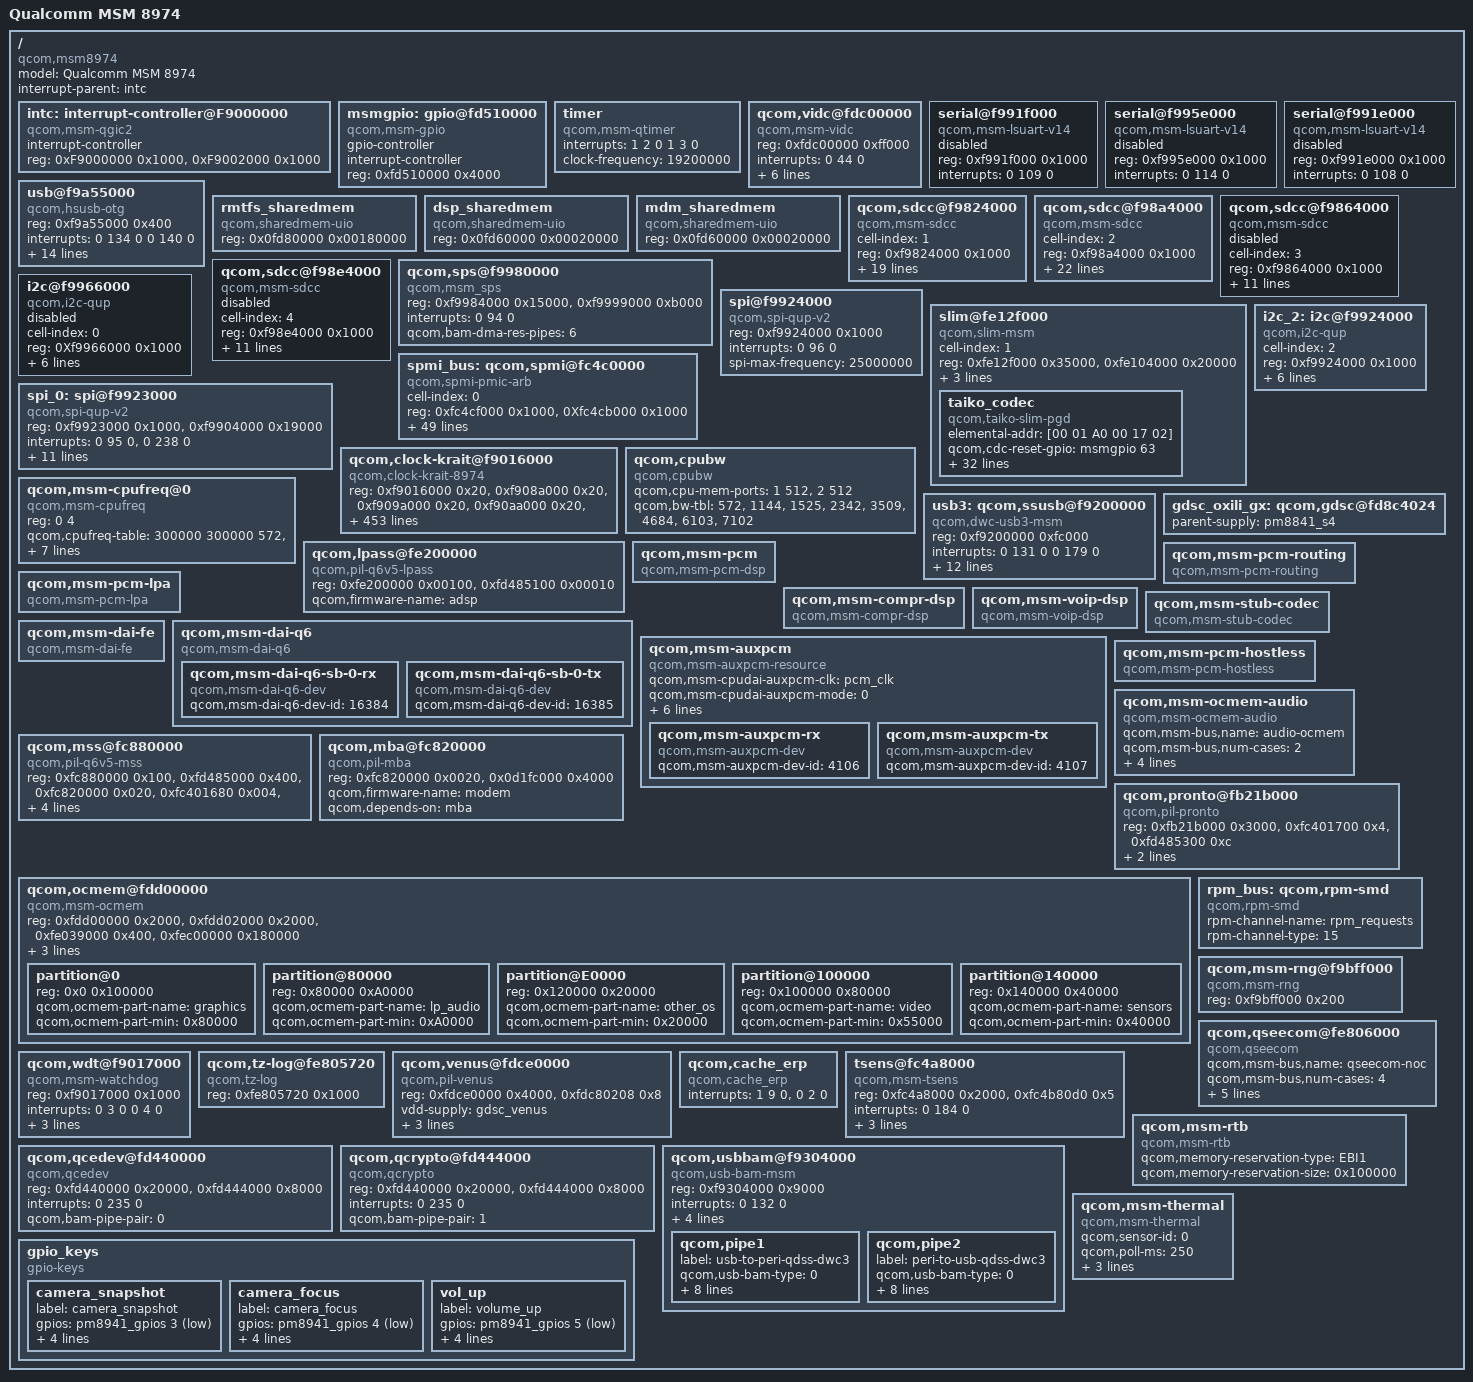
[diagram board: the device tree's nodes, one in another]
/* Copyright (c) 2012, The Linux Foundation. All rights reserved.
 *
 * This program is free software; you can redistribute it and/or modify
 * it under the terms of the GNU General Public License version 2 and
 * only version 2 as published by the Free Software Foundation.
 *
 * This program is distributed in the hope that it will be useful,
 * but WITHOUT ANY WARRANTY; without even the implied warranty of
 * MERCHANTABILITY or FITNESS FOR A PARTICULAR PURPOSE.  See the
 * GNU General Public License for more details.
 */

/include/ "skeleton.dtsi"
/include/ "msm8974_pm.dtsi"
/include/ "msm8974-iommu.dtsi"
/include/ "msm8974-camera.dtsi"
/include/ "msm8974-coresight.dtsi"
/include/ "msm-gdsc.dtsi"
/include/ "msm8974-ion.dtsi"
/include/ "msm8974-gpu.dtsi"
/include/ "msm8974-mdss.dtsi"

/ {
	model = "Qualcomm MSM 8974";
	compatible = "qcom,msm8974";
	interrupt-parent = <&intc>;

	intc: interrupt-controller@F9000000 {
		compatible = "qcom,msm-qgic2";
		interrupt-controller;
		#interrupt-cells = <3>;
		reg = <0xF9000000 0x1000>,
		      <0xF9002000 0x1000>;
	};

	msmgpio: gpio@fd510000 {
		compatible = "qcom,msm-gpio";
		gpio-controller;
		#gpio-cells = <2>;
		interrupt-controller;
		#interrupt-cells = <2>;
		reg = <0xfd510000 0x4000>;
	};

	timer {
		compatible = "qcom,msm-qtimer", "arm,armv7-timer";
		interrupts = <1 2 0 1 3 0>;
		clock-frequency = <19200000>;
	};

	qcom,vidc@fdc00000 {
		compatible = "qcom,msm-vidc";
		reg = <0xfdc00000 0xff000>;
		interrupts = <0 44 0>;
		vidc-cp-map = <0x1000000 0x40000000>;
		vidc-ns-map = <0x40000000 0x40000000>;
		load-freq-tbl = <979200 410000000>,
				<560145 266670000>,
				<421161 200000000>,
				<243000 133330000>,
				<108000 100000000>,
				<36000 50000000>;
	};

	serial@f991f000 {
		compatible = "qcom,msm-lsuart-v14";
		reg = <0xf991f000 0x1000>;
		interrupts = <0 109 0>;
		status = "disabled";
	};

	serial@f995e000 {
		compatible = "qcom,msm-lsuart-v14";
		reg = <0xf995e000 0x1000>;
		interrupts = <0 114 0>;
		status = "disabled";
	};

	serial@f991e000 {
		compatible = "qcom,msm-lsuart-v14";
		reg = <0xf991e000 0x1000>;
		interrupts = <0 108 0>;
		status = "disabled";
	};

	usb@f9a55000 {
		compatible = "qcom,hsusb-otg";
		reg = <0xf9a55000 0x400>;
		interrupts = <0 134 0 0 140 0>;
		interrupt-names = "core_irq", "async_irq";
		HSUSB_VDDCX-supply = <&pm8841_s2>;
		HSUSB_1p8-supply = <&pm8941_l6>;
		HSUSB_3p3-supply = <&pm8941_l24>;

		qcom,hsusb-otg-phy-type = <2>;
		qcom,hsusb-otg-mode = <1>;
		qcom,hsusb-otg-otg-control = <1>;
		qcom,hsusb-otg-disable-reset;
		qcom,hsusb-otg-pnoc-errata-fix;

		qcom,msm-bus,name = "usb2";
		qcom,msm-bus,num-cases = <2>;
		qcom,msm-bus,active-only = <0>;
		qcom,msm-bus,num-paths = <1>;
		qcom,msm-bus,vectors-KBps =
				<87 512 0 0>,
				<87 512 60000 960000>;
	};

	rmtfs_sharedmem {
		compatible = "qcom,sharedmem-uio";
		reg = <0x0fd80000 0x00180000>;
		reg-names = "rmtfs";
	};

	dsp_sharedmem {
		compatible = "qcom,sharedmem-uio";
		reg = <0x0fd60000 0x00020000>;
		reg-names = "rfsa_dsp";
	};

	mdm_sharedmem {
		compatible = "qcom,sharedmem-uio";
		reg = <0x0fd60000 0x00020000>;
		reg-names = "rfsa_mdm";
	};

	qcom,sdcc@f9824000 {
		cell-index = <1>; /* SDC1 eMMC slot */
		compatible = "qcom,msm-sdcc";
		reg = <0xf9824000 0x1000>;
		reg-names = "core_mem";
		interrupts = <0 123 0>;
		interrupt-names = "core_irq";
		vdd-supply = <&pm8941_l20>;
		vdd-io-supply = <&pm8941_s3>;

		qcom,sdcc-vdd-voltage_level = <2950000 2950000>;
		qcom,sdcc-vdd-current_level = <800 500000>;

		qcom,sdcc-vdd-io-always_on;
		qcom,sdcc-vdd-io-voltage_level = <1800000 1800000>;
		qcom,sdcc-vdd-io-current_level = <250 154000>;

		qcom,sdcc-pad-pull-on = <0x0 0x3 0x3>; /* no-pull, pull-up, pull-up */
		qcom,sdcc-pad-pull-off = <0x0 0x3 0x3>; /* no-pull, pull-up, pull-up */
		qcom,sdcc-pad-drv-on = <0x7 0x4 0x4>; /* 16mA, 10mA, 10mA */
		qcom,sdcc-pad-drv-off = <0x0 0x0 0x0>; /* 2mA, 2mA, 2mA */

		qcom,sdcc-clk-rates = <400000 25000000 50000000 100000000 200000000>;
		qcom,sdcc-sup-voltages = <2950 2950>;
		qcom,sdcc-bus-width = <8>;
		qcom,sdcc-nonremovable;
		qcom,sdcc-bus-speed-mode = "HS200_1p8v", "DDR_1p8v";
	};

	qcom,sdcc@f98a4000 {
		cell-index = <2>; /* SDC2 SD card slot */
		compatible = "qcom,msm-sdcc";
		reg = <0xf98a4000 0x1000>;
		reg-names = "core_mem";
		interrupts = <0 125 0>;
		interrupt-names = "core_irq";
		vdd-supply = <&pm8941_l21>;
		vdd-io-supply = <&pm8941_l13>;

		qcom,sdcc-vdd-voltage_level = <2950000 2950000>;
		qcom,sdcc-vdd-current_level = <9000 800000>;

		qcom,sdcc-vdd-io-always_on;
		qcom,sdcc-vdd-io-lpm_sup;
		qcom,sdcc-vdd-io-voltage_level = <1800000 2950000>;
		qcom,sdcc-vdd-io-current_level = <6 22000>;

		qcom,sdcc-pad-pull-on = <0x0 0x3 0x3>; /* no-pull, pull-up, pull-up */
		qcom,sdcc-pad-pull-off = <0x0 0x3 0x3>; /* no-pull, pull-up, pull-up */
		qcom,sdcc-pad-drv-on = <0x7 0x4 0x4>; /* 16mA, 10mA, 10mA */
		qcom,sdcc-pad-drv-off = <0x0 0x0 0x0>; /* 2mA, 2mA, 2mA */

		qcom,sdcc-clk-rates = <400000 25000000 50000000 100000000 200000000>;
		qcom,sdcc-sup-voltages = <2950 2950>;
		qcom,sdcc-bus-width = <4>;
		qcom,sdcc-xpc;
		qcom,sdcc-bus-speed-mode = "SDR12", "SDR25", "SDR50", "DDR50", "SDR104";
		qcom,sdcc-current-limit = <800>;
	};

	qcom,sdcc@f9864000 {
		cell-index = <3>; /* SDC3 SDIO slot */
		compatible = "qcom,msm-sdcc";
		reg = <0xf9864000 0x1000>;
		reg-names = "core_mem";
		interrupts = <0 127 0>;
		interrupt-names = "core_irq";

		gpios = <&msmgpio 40 0>, /* CLK */
			<&msmgpio 39 0>, /* CMD */
			<&msmgpio 38 0>, /* DATA0 */
			<&msmgpio 37 0>, /* DATA1 */
			<&msmgpio 36 0>, /* DATA2 */
			<&msmgpio 35 0>; /* DATA3 */
		qcom,sdcc-gpio-names = "CLK", "CMD", "DAT0", "DAT1", "DAT2", "DAT3";

		qcom,sdcc-clk-rates = <400000 25000000 50000000 100000000>;
		qcom,sdcc-sup-voltages = <1800 1800>;
		qcom,sdcc-bus-width = <4>;
		qcom,sdcc-bus-speed-mode = "SDR12", "SDR25", "SDR50", "DDR50";
		status = "disable";
	};

	qcom,sdcc@f98e4000 {
		cell-index = <4>; /* SDC4 SDIO slot */
		compatible = "qcom,msm-sdcc";
		reg = <0xf98e4000 0x1000>;
		reg-names = "core_mem";
		interrupts = <0 129 0>;
		interrupt-names = "core_irq";

		gpios = <&msmgpio 93 0>, /* CLK */
			<&msmgpio 91 0>, /* CMD */
			<&msmgpio 96 0>, /* DATA0 */
			<&msmgpio 95 0>, /* DATA1 */
			<&msmgpio 94 0>, /* DATA2 */
			<&msmgpio 92 0>; /* DATA3 */
		qcom,sdcc-gpio-names = "CLK", "CMD", "DAT0", "DAT1", "DAT2", "DAT3";

		qcom,sdcc-clk-rates = <400000 25000000 50000000 100000000>;
		qcom,sdcc-sup-voltages = <1800 1800>;
		qcom,sdcc-bus-width = <4>;
		qcom,sdcc-bus-speed-mode = "SDR12", "SDR25", "SDR50", "DDR50";
		status = "disable";
	};

	qcom,sps@f9980000 {
		compatible = "qcom,msm_sps";
		reg = <0xf9984000 0x15000>,
		      <0xf9999000 0xb000>;
		interrupts = <0 94 0>;

		qcom,bam-dma-res-pipes = <6>;
	};


	spi@f9924000 {
		compatible = "qcom,spi-qup-v2";
		reg = <0xf9924000 0x1000>;
		interrupts = <0 96 0>;
		spi-max-frequency = <25000000>;
	};

	slim@fe12f000 {
		cell-index = <1>;
		compatible = "qcom,slim-msm";
		reg = <0xfe12f000 0x35000>,
		      <0xfe104000 0x20000>;
		reg-names = "slimbus_physical", "slimbus_bam_physical";
		interrupts = <0 163 0 0 164 0>;
		interrupt-names = "slimbus_irq", "slimbus_bam_irq";
		qcom,min-clk-gear = <10>;
		qcom,rxreg-access;

		taiko_codec {
			compatible = "qcom,taiko-slim-pgd";
			elemental-addr = [00 01 A0 00 17 02];

			qcom,cdc-reset-gpio = <&msmgpio 63 0>;

			cdc-vdd-buck-supply = <&pm8941_s2>;
			qcom,cdc-vdd-buck-voltage = <2150000 2150000>;
			qcom,cdc-vdd-buck-current = <650000>;

			cdc-vdd-tx-h-supply = <&pm8941_s3>;
			qcom,cdc-vdd-tx-h-voltage = <1800000 1800000>;
			qcom,cdc-vdd-tx-h-current = <25000>;

			cdc-vdd-rx-h-supply = <&pm8941_s3>;
			qcom,cdc-vdd-rx-h-voltage = <1800000 1800000>;
			qcom,cdc-vdd-rx-h-current = <25000>;

			cdc-vddpx-1-supply = <&pm8941_s3>;
			qcom,cdc-vddpx-1-voltage = <1800000 1800000>;
			qcom,cdc-vddpx-1-current = <10000>;

			cdc-vdd-a-1p2v-supply = <&pm8941_l1>;
			qcom,cdc-vdd-a-1p2v-voltage = <1225000 1225000>;
			qcom,cdc-vdd-a-1p2v-current = <10000>;

			cdc-vddcx-1-supply = <&pm8941_l1>;
			qcom,cdc-vddcx-1-voltage = <1225000 1225000>;
			qcom,cdc-vddcx-1-current = <10000>;

			cdc-vddcx-2-supply = <&pm8941_l1>;
			qcom,cdc-vddcx-2-voltage = <1225000 1225000>;
			qcom,cdc-vddcx-2-current = <10000>;

			qcom,cdc-micbias-ldoh-v = <0x3>;
			qcom,cdc-micbias-cfilt1-mv = <1800>;
			qcom,cdc-micbias-cfilt2-mv = <2700>;
			qcom,cdc-micbias-cfilt3-mv = <1800>;
			qcom,cdc-micbias1-cfilt-sel = <0x0>;
			qcom,cdc-micbias2-cfilt-sel = <0x1>;
			qcom,cdc-micbias3-cfilt-sel = <0x2>;
			qcom,cdc-micbias4-cfilt-sel = <0x2>;

			qcom,cdc-slim-ifd = "taiko-slim-ifd";
			qcom,cdc-slim-ifd-elemental-addr = [00 00 A0 00 17 02];
		};
	};

	spmi_bus: qcom,spmi@fc4c0000 {
		cell-index = <0>;
		compatible = "qcom,spmi-pmic-arb";
		reg = <0xfc4cf000 0x1000>,
		      <0Xfc4cb000 0x1000>;
		/* 190,ee0_krait_hlos_spmi_periph_irq */
		/* 187,channel_0_krait_hlos_trans_done_irq */
		interrupts = <0 190 0 0 187 0>;
		qcom,pmic-arb-ee = <0>;
		qcom,pmic-arb-channel = <0>;
		qcom,pmic-arb-ppid-map = <0x40400000>, /* BUS */
					 <0x40500001>, /* INT */
					 <0x40600002>, /* SPMI */
					 <0x40800003>, /* PON */
					 <0x42400004>, /* TEMP_ALARM */
					 <0x47000005>, /* PBS_CORE */
					 <0x47100006>, /* PBS_CLIENT0 */
					 <0x47200007>, /* PBS_CLIENT1 */
					 <0x47300008>, /* PBS_CLIENT2 */
					 <0x47400009>, /* PBS_CLIENT3 */
					 <0x4750000a>, /* PBS_CLIENT4 */
					 <0x4760000b>, /* PBS_CLIENT5 */
					 <0x4770000c>, /* PBS_CLIENT6 */
					 <0x4780000d>, /* PBS_CLIENT7 */
					 <0x4a00000e>, /* MPP1 */
					 <0x4a100021>, /* MPP2 */
					 <0x4a20000f>, /* MPP3 */
					 <0x4a300010>, /* MPP4 */
					 <0x51000011>, /* BCLK_GEN_MAIN */
					 <0x51d00012>, /* S4_CTRL */
					 <0x51e00013>, /* S4_PS */
					 <0x51f00014>, /* S4_FREQ */
					 <0x52000015>, /* S5_CTRL */
					 <0x52100016>, /* S5_PS */
					 <0x52200017>, /* S5_FREQ */
					 <0x52300018>, /* S6_CTRL */
					 <0x52400019>, /* S6_PS */
					 <0x5250001a>, /* S6_FREQ */
					 <0x5260001b>, /* S7_CTRL */
					 <0x5270001c>, /* S7_PS */
					 <0x5280001d>, /* S7_FREQ */
					 <0x5290001e>, /* S8_CTRL */
					 <0x52a0001f>, /* S8_PS */
					 <0x52b00020>, /* S8_FREQ */
					 <0x00400022>, /* BUS */
					 <0x00500023>, /* INT */
					 <0x00600024>, /* SPMI */
					 <0x00800025>, /* PON */
					 <0x00b00027>, /* VREG_TFT */
					 <0x01000028>, /* SMBB_CHGR */
					 <0x01100029>, /* SMBB_BUCK */
					 <0x0120002a>, /* SMBB_BAT_IF */
					 <0x0130002b>, /* SMBB_USB_CHGPTH */
					 <0x0140002c>, /* SMBB_DC_CHGPTH */
					 <0x0150002d>, /* SMBB_BOOST */
					 <0x0160002e>, /* SMBB_MISC */
					 <0x0170002f>, /* SMBB_FREQ */
					 <0x02400030>, /* TEMP_ALARM */
					 <0x02800031>, /* COIN */
					 <0x03100032>, /* VADC1_USR */
					 <0x03300033>, /* VADC1_BMS */
					 <0x03400034>, /* VADC2_BTM */
					 <0x03600035>, /* IADC1_USR */
					 <0x03800036>, /* IADC1_BMS */
					 <0x04000037>, /* BMS1 */
					 <0x05700039>, /* DIFF_CLK1 */
					 <0x05c0003b>, /* DIV_CLK2 */
					 <0x0610003d>, /* RTC_ALARM */
					 <0x0620003e>, /* RTC_TIMER */
					 <0x07100040>, /* PBS_CLIENT0 */
					 <0x07200041>, /* PBS_CLIENT1 */
					 <0x07300042>, /* PBS_CLIENT2 */
					 <0x07400043>, /* PBS_CLIENT3 */
					 <0x07500044>, /* PBS_CLIENT4 */
					 <0x07600045>, /* PBS_CLIENT5 */
					 <0x07700046>, /* PBS_CLIENT6 */
					 <0x07800047>, /* PBS_CLIENT7 */
					 <0x07900048>, /* PBS_CLIENT8 */
					 <0x07a00049>, /* PBS_CLIENT9 */
					 <0x07b0004a>, /* PBS_CLIENT10 */
					 <0x07c0004b>, /* PBS_CLIENT11 */
					 <0x07d0004c>, /* PBS_CLIENT12 */
					 <0x07e0004d>, /* PBS_CLIENT13 */
					 <0x07f0004e>, /* PBS_CLIENT14 */
					 <0x0800004f>, /* PBS_CLIENT15 */
					 <0x0a100050>, /* MPP2 */
					 <0x0a300051>, /* MPP4 */
					 <0x0a400052>, /* MPP5 */
					 <0x0a500053>, /* MPP6 */
					 <0x0a600054>, /* MPP7 */
					 <0x0a700055>, /* MPP8 */
					 <0x0c000056>, /* GPIO1 */
					 <0x0c100057>, /* GPIO2 */
					 <0x0c200058>, /* GPIO3 */
					 <0x0c300059>, /* GPIO4 */
					 <0x0c40005a>, /* GPIO5 */
					 <0x0c50005b>, /* GPIO6 */
					 <0x0c60005c>, /* GPIO7 */
					 <0x0c70005d>, /* GPIO8 */
					 <0x0c80005e>, /* GPIO9 */
					 <0x0c90005f>, /* GPIO10 */
					 <0x0ca00060>, /* GPIO11 */
					 <0x0cb00061>, /* GPIO12 */
					 <0x0cc00062>, /* GPIO13 */
					 <0x0cd00063>, /* GPIO14 */
					 <0x0ce00064>, /* GPIO15 */
					 <0x0cf00065>, /* GPIO16 */
					 <0x0d200066>, /* GPIO19 */
					 <0x0d300067>, /* GPIO20 */
					 <0x0d500068>, /* GPIO22 */
					 <0x0d600069>, /* GPIO23 */
					 <0x0d70006a>, /* GPIO24 */
					 <0x0d80006b>, /* GPIO25 */
					 <0x0d90006c>, /* GPIO26 */
					 <0x0da0006d>, /* GPIO27 */
					 <0x0dc0006e>, /* GPIO29 */
					 <0x0dd0006f>, /* GPIO30 */
					 <0x0df00070>, /* GPIO32 */
					 <0x0e000071>, /* GPIO33 */
					 <0x0e100072>, /* GPIO34 */
					 <0x0e200073>, /* GPIO35 */
					 <0x0e300074>, /* GPIO36 */
					 <0x11000075>, /* BUCK_CMN */
					 <0x1a000076>, /* BOOST */
					 <0x1a100077>, /* BOOST_FREQ */
					 <0x1a800078>, /* KEYPAD1 */
					 <0x1b000079>, /* LPG_LUT */
					 <0x1b10007a>, /* LPG_CHAN1 */
					 <0x1b20007b>, /* LPG_CHAN2 */
					 <0x1b30007c>, /* LPG_CHAN3 */
					 <0x1b40007d>, /* LPG_CHAN4 */
					 <0x1b50007e>, /* LPG_CHAN5 */
					 <0x1b60007f>, /* LPG_CHAN6 */
					 <0x1b700080>, /* LPG_CHAN7 */
					 <0x1b800081>, /* LPG_CHAN8 */
					 <0x1bc00082>, /* PWM_3D */
					 <0x1c000083>, /* VIB1 */
					 <0x1d000084>, /* TRI_LED */
					 <0x1d300085>, /* FLASH1 */
					 <0x1d800086>, /* WLED1 */
					 <0x1e200087>, /* KPDBL_MAIN */
					 <0x1e300088>, /* KPDBL_LUT */
					 <0x1e400089>, /* LPG_CHAN9 */
					 <0x1e50008a>, /* LPG_CHAN10 */
					 <0x1e60008b>, /* LPG_CHAN11 */
					 <0x1e70008c>; /* LPG_CHAN12 */
	};

	i2c@f9966000 {
		cell-index = <0>;
		compatible = "qcom,i2c-qup";
		reg = <0Xf9966000 0x1000>;
		reg-names = "qup_phys_addr";
		interrupts = <0 104 0>;
		interrupt-names = "qup_err_intr";
		qcom,i2c-bus-freq = <100000>;
		qcom,i2c-src-freq = <19200000>;
		qcom,scl-gpio = <&msmgpio 3 0>;
		qcom,sda-gpio = <&msmgpio 2 0>;
		qcom,master-id = <86>;
		status = "disabled";
	};

	i2c_2: i2c@f9924000 {
		cell-index = <2>;
		compatible = "qcom,i2c-qup";
		reg = <0xf9924000 0x1000>;
		#address-cells = <1>;
		#size-cells = <0>;
		reg-names = "qup_phys_addr";
		interrupts = <0 96 0>;
		interrupt-names = "qup_err_intr";
		qcom,i2c-bus-freq = <384000>;
		qcom,i2c-src-freq = <19200000>;
		qcom,master-id = <86>;
		qcom,scl-gpio = <&msmgpio 7 0>;
		qcom,sda-gpio = <&msmgpio 6 0>;
	};

	spi_0: spi@f9923000 { /* BLSP1 QUP1 */
		compatible = "qcom,spi-qup-v2";
		#address-cells = <1>;
		#size-cells = <0>;
		reg-names = "spi_physical", "spi_bam_physical";
		reg = <0xf9923000 0x1000>,
		      <0xf9904000 0x19000>;
		interrupt-names = "spi_irq", "spi_bam_irq";
		interrupts = <0 95 0>, <0 238 0>;
		spi-max-frequency = <19200000>;

		qcom,gpio-mosi = <&msmgpio 0 0>;
		qcom,gpio-miso = <&msmgpio 1 0>;
		qcom,gpio-clk  = <&msmgpio 3 0>;
		qcom,gpio-cs0  = <&msmgpio 9 0>;

		qcom,infinite-mode = <0>;
		qcom,use-bam;
		qcom,ver-reg-exists;
		qcom,bam-consumer-pipe-index = <12>;
		qcom,bam-producer-pipe-index = <13>;
		qcom,master-id = <86>;
	};

	qcom,clock-krait@f9016000 {
		compatible = "qcom,clock-krait-8974";
		reg = <0xf9016000 0x20>,
			<0xf908a000 0x20>,
			<0xf909a000 0x20>,
			<0xf90aa000 0x20>,
			<0xf90ba000 0x20>,
			<0xfc4b80b0 0x08>;
		reg-names = "hfpll_l2_clk", "hfpll0_clk",
				"hfpll1_clk", "hfpll2_clk",
				"hfpll3_clk", "efuse";
		cpu0-supply = <&krait0_vreg>;
		cpu1-supply = <&krait1_vreg>;
		cpu2-supply = <&krait2_vreg>;
		cpu3-supply = <&krait3_vreg>;
		l2-dig-supply = <&pm8841_s2_corner_ao>;
		hfpll-dig-supply = <&pm8841_s2_corner_ao>;
		hfpll-analog-supply = <&pm8941_l12_ao>;
		qcom,hfpll-config-val = <0x04D0405D>;
                qcom,hfpll-user-vco-mask = <0x00100000>;

		qcom,l2-fmax =
			<          0 0			 >,
			<  576000000 4 /* SVS_SOC */	 >,
			< 1036800000 5 /* NORMAL */	 >,
			< 1728000000 7 /* SUPER_TURBO */ >;

		qcom,speed0-pvs0-bin-v0 =
			<          0       0   0 >,
			<  300000000  815000  73 >,
			<  345600000  825000  85 >,
			<  422400000  835000 104 >,
			<  499200000  845000 124 >,
			<  576000000  855000 144 >,
			<  652800000  865000 165 >,
			<  729600000  875000 186 >,
			<  806400000  890000 208 >,
			<  883200000  900000 229 >,
			<  960000000  915000 252 >,
			< 1036800000  925000 275 >,
			< 1113600000  940000 298 >,
			< 1190400000  950000 321 >,
			< 1267200000  965000 346 >,
			< 1344000000  980000 371 >,
			< 1420800000  995000 397 >,
			< 1497600000 1010000 423 >,
			< 1574400000 1025000 450 >,
			< 1651200000 1040000 477 >,
			< 1728000000 1055000 506 >,
			< 1804800000 1070000 536 >,
			< 1881600000 1085000 567 >,
			< 1958400000 1100000 598 >;

		qcom,speed0-pvs1-bin-v0 =
			<          0       0   0 >,
			<  300000000  800000  73 >,
			<  345600000  810000  85 >,
			<  422400000  820000 104 >,
			<  499200000  830000 124 >,
			<  576000000  840000 144 >,
			<  652800000  850000 165 >,
			<  729600000  860000 186 >,
			<  806400000  875000 208 >,
			<  883200000  885000 229 >,
			<  960000000  895000 252 >,
			< 1036800000  910000 275 >,
			< 1113600000  920000 298 >,
			< 1190400000  930000 321 >,
			< 1267200000  945000 346 >,
			< 1344000000  960000 371 >,
			< 1420800000  975000 397 >,
			< 1497600000  990000 423 >,
			< 1574400000 1005000 450 >,
			< 1651200000 1020000 477 >,
			< 1728000000 1030000 506 >,
			< 1804800000 1045000 536 >,
			< 1881600000 1060000 567 >,
			< 1958400000 1075000 598 >;

		qcom,speed0-pvs2-bin-v0 =
			<          0       0   0 >,
			<  300000000  785000  73 >,
			<  345600000  795000  85 >,
			<  422400000  805000 104 >,
			<  499200000  815000 124 >,
			<  576000000  825000 144 >,
			<  652800000  835000 165 >,
			<  729600000  845000 186 >,
			<  806400000  855000 208 >,
			<  883200000  865000 229 >,
			<  960000000  875000 252 >,
			< 1036800000  890000 275 >,
			< 1113600000  900000 298 >,
			< 1190400000  910000 321 >,
			< 1267200000  925000 346 >,
			< 1344000000  940000 371 >,
			< 1420800000  955000 397 >,
			< 1497600000  970000 423 >,
			< 1574400000  980000 450 >,
			< 1651200000  995000 477 >,
			< 1728000000 1005000 506 >,
			< 1804800000 1020000 536 >,
			< 1881600000 1035000 567 >,
			< 1958400000 1050000 598 >;

		qcom,speed0-pvs3-bin-v0 =
			<          0       0   0 >,
			<  300000000  775000  73 >,
			<  345600000  780000  85 >,
			<  422400000  790000 104 >,
			<  499200000  800000 124 >,
			<  576000000  810000 144 >,
			<  652800000  820000 165 >,
			<  729600000  830000 186 >,
			<  806400000  840000 208 >,
			<  883200000  850000 229 >,
			<  960000000  860000 252 >,
			< 1036800000  875000 275 >,
			< 1113600000  885000 298 >,
			< 1190400000  895000 321 >,
			< 1267200000  910000 346 >,
			< 1344000000  925000 371 >,
			< 1420800000  935000 397 >,
			< 1497600000  950000 423 >,
			< 1574400000  960000 450 >,
			< 1651200000  970000 477 >,
			< 1728000000  985000 506 >,
			< 1804800000  995000 536 >,
			< 1881600000 1010000 567 >,
			< 1958400000 1025000 598 >;

		qcom,speed0-pvs4-bin-v0 =
			<          0       0   0 >,
			<  300000000  775000  73 >,
			<  345600000  775000  85 >,
			<  422400000  780000 104 >,
			<  499200000  790000 124 >,
			<  576000000  800000 144 >,
			<  652800000  810000 165 >,
			<  729600000  820000 186 >,
			<  806400000  830000 208 >,
			<  883200000  840000 229 >,
			<  960000000  850000 252 >,
			< 1036800000  860000 275 >,
			< 1113600000  870000 298 >,
			< 1190400000  880000 321 >,
			< 1267200000  895000 346 >,
			< 1344000000  910000 371 >,
			< 1420800000  920000 397 >,
			< 1497600000  930000 423 >,
			< 1574400000  940000 450 >,
			< 1651200000  950000 477 >,
			< 1728000000  960000 506 >,
			< 1804800000  975000 536 >,
			< 1881600000  985000 567 >,
			< 1958400000 1000000 598 >;

		qcom,speed0-pvs5-bin-v0 =
			<          0       0   0 >,
			<  300000000  750000  73 >,
			<  345600000  760000  85 >,
			<  422400000  770000 104 >,
			<  499200000  780000 124 >,
			<  576000000  790000 144 >,
			<  652800000  800000 165 >,
			<  729600000  810000 186 >,
			<  806400000  820000 208 >,
			<  883200000  830000 229 >,
			<  960000000  840000 252 >,
			< 1036800000  850000 275 >,
			< 1113600000  860000 298 >,
			< 1190400000  870000 321 >,
			< 1267200000  880000 346 >,
			< 1344000000  890000 371 >,
			< 1420800000  900000 397 >,
			< 1497600000  910000 423 >,
			< 1574400000  920000 450 >,
			< 1651200000  930000 477 >,
			< 1728000000  940000 506 >,
			< 1804800000  955000 536 >,
			< 1881600000  965000 567 >,
			< 1958400000  975000 598 >;

		qcom,speed0-pvs6-bin-v0 =
			<          0       0   0 >,
			<  300000000  750000  73 >,
			<  345600000  750000  85 >,
			<  422400000  760000 104 >,
			<  499200000  770000 124 >,
			<  576000000  780000 144 >,
			<  652800000  790000 165 >,
			<  729600000  800000 186 >,
			<  806400000  810000 208 >,
			<  883200000  820000 229 >,
			<  960000000  830000 252 >,
			< 1036800000  840000 275 >,
			< 1113600000  850000 298 >,
			< 1190400000  860000 321 >,
			< 1267200000  870000 346 >,
			< 1344000000  875000 371 >,
			< 1420800000  885000 397 >,
			< 1497600000  895000 423 >,
			< 1574400000  905000 450 >,
			< 1651200000  915000 477 >,
			< 1728000000  920000 506 >,
			< 1804800000  930000 536 >,
			< 1881600000  940000 567 >,
			< 1958400000  950000 598 >;

		qcom,speed2-pvs0-bin-v0 =
			<          0       0   0 >,
			<  300000000  800000  72 >,
			<  345600000  800000  83 >,
			<  422400000  805000 102 >,
			<  499200000  815000 121 >,
			<  576000000  825000 141 >,
			<  652800000  835000 161 >,
			<  729600000  845000 181 >,
			<  806400000  855000 202 >,
			<  883200000  865000 223 >,
			<  960000000  875000 245 >,
			< 1036800000  890000 267 >,
			< 1113600000  900000 289 >,
			< 1190400000  915000 313 >,
			< 1267200000  925000 336 >,
			< 1344000000  940000 360 >,
			< 1420800000  950000 383 >,
			< 1497600000  965000 409 >,
			< 1574400000  980000 435 >,
			< 1651200000  995000 461 >,
			< 1728000000 1010000 488 >,
			< 1804800000 1025000 516 >,
			< 1881600000 1040000 543 >,
			< 1958400000 1055000 573 >,
			< 2035200000 1070000 604 >,
			< 2112000000 1085000 636 >,
			< 2150400000 1100000 656 >;

		qcom,speed2-pvs1-bin-v0 =
			<          0       0   0 >,
			<  300000000  800000  72 >,
			<  345600000  800000  83 >,
			<  422400000  800000 102 >,
			<  499200000  800000 121 >,
			<  576000000  810000 141 >,
			<  652800000  820000 161 >,
			<  729600000  830000 181 >,
			<  806400000  840000 202 >,
			<  883200000  850000 223 >,
			<  960000000  860000 245 >,
			< 1036800000  875000 267 >,
			< 1113600000  885000 289 >,
			< 1190400000  895000 313 >,
			< 1267200000  910000 336 >,
			< 1344000000  920000 360 >,
			< 1420800000  930000 383 >,
			< 1497600000  945000 409 >,
			< 1574400000  960000 435 >,
			< 1651200000  975000 461 >,
			< 1728000000  990000 488 >,
			< 1804800000 1005000 516 >,
			< 1881600000 1020000 543 >,
			< 1958400000 1030000 573 >,
			< 2035200000 1045000 604 >,
			< 2112000000 1060000 636 >,
			< 2150400000 1075000 656 >;

		qcom,speed2-pvs2-bin-v0 =
			<          0       0   0 >,
			<  300000000  775000  72 >,
			<  345600000  775000  83 >,
			<  422400000  775000 102 >,
			<  499200000  785000 121 >,
			<  576000000  795000 141 >,
			<  652800000  805000 161 >,
			<  729600000  815000 181 >,
			<  806400000  825000 202 >,
			<  883200000  835000 223 >,
			<  960000000  845000 245 >,
			< 1036800000  855000 267 >,
			< 1113600000  865000 289 >,
			< 1190400000  875000 313 >,
			< 1267200000  890000 336 >,
			< 1344000000  900000 360 >,
			< 1420800000  910000 383 >,
			< 1497600000  925000 409 >,
			< 1574400000  940000 435 >,
			< 1651200000  955000 461 >,
			< 1728000000  970000 488 >,
			< 1804800000  980000 516 >,
			< 1881600000  995000 543 >,
			< 1958400000 1005000 573 >,
			< 2035200000 1020000 604 >,
			< 2112000000 1035000 636 >,
			< 2150400000 1050000 656 >;

		qcom,speed2-pvs3-bin-v0 =
			<          0       0   0 >,
			<  300000000  775000  72 >,
			<  345600000  775000  83 >,
			<  422400000  775000 102 >,
			<  499200000  775000 121 >,
			<  576000000  780000 141 >,
			<  652800000  790000 161 >,
			<  729600000  800000 181 >,
			<  806400000  810000 202 >,
			<  883200000  820000 223 >,
			<  960000000  830000 245 >,
			< 1036800000  840000 267 >,
			< 1113600000  850000 289 >,
			< 1190400000  860000 313 >,
			< 1267200000  875000 336 >,
			< 1344000000  885000 360 >,
			< 1420800000  895000 383 >,
			< 1497600000  910000 409 >,
			< 1574400000  925000 435 >,
			< 1651200000  935000 461 >,
			< 1728000000  950000 488 >,
			< 1804800000  960000 516 >,
			< 1881600000  970000 543 >,
			< 1958400000  985000 573 >,
			< 2035200000  995000 604 >,
			< 2112000000 1010000 636 >,
			< 2150400000 1025000 656 >;

		qcom,speed2-pvs4-bin-v0 =
			<          0       0   0 >,
			<  300000000  775000  72 >,
			<  345600000  775000  83 >,
			<  422400000  775000 102 >,
			<  499200000  775000 121 >,
			<  576000000  775000 141 >,
			<  652800000  780000 161 >,
			<  729600000  790000 181 >,
			<  806400000  800000 202 >,
			<  883200000  810000 223 >,
			<  960000000  820000 245 >,
			< 1036800000  830000 267 >,
			< 1113600000  840000 289 >,
			< 1190400000  850000 313 >,
			< 1267200000  860000 336 >,
			< 1344000000  870000 360 >,
			< 1420800000  880000 383 >,
			< 1497600000  895000 409 >,
			< 1574400000  910000 435 >,
			< 1651200000  920000 461 >,
			< 1728000000  930000 488 >,
			< 1804800000  940000 516 >,
			< 1881600000  950000 543 >,
			< 1958400000  960000 573 >,
			< 2035200000  975000 604 >,
			< 2112000000  985000 636 >,
			< 2150400000 1000000 656 >;

		qcom,speed2-pvs5-bin-v0 =
			<          0       0   0 >,
			<  300000000  750000  72 >,
			<  345600000  750000  83 >,
			<  422400000  750000 102 >,
			<  499200000  750000 121 >,
			<  576000000  760000 141 >,
			<  652800000  770000 161 >,
			<  729600000  780000 181 >,
			<  806400000  790000 202 >,
			<  883200000  800000 223 >,
			<  960000000  810000 245 >,
			< 1036800000  820000 267 >,
			< 1113600000  830000 289 >,
			< 1190400000  840000 313 >,
			< 1267200000  850000 336 >,
			< 1344000000  860000 360 >,
			< 1420800000  870000 383 >,
			< 1497600000  880000 409 >,
			< 1574400000  890000 435 >,
			< 1651200000  900000 461 >,
			< 1728000000  910000 488 >,
			< 1804800000  920000 516 >,
			< 1881600000  930000 543 >,
			< 1958400000  940000 573 >,
			< 2035200000  955000 604 >,
			< 2112000000  965000 636 >,
			< 2150400000  975000 656 >;

		qcom,speed2-pvs6-bin-v0 =
			<          0       0   0 >,
			<  300000000  750000  72 >,
			<  345600000  750000  83 >,
			<  422400000  750000 102 >,
			<  499200000  750000 121 >,
			<  576000000  750000 141 >,
			<  652800000  760000 161 >,
			<  729600000  770000 181 >,
			<  806400000  780000 202 >,
			<  883200000  790000 223 >,
			<  960000000  800000 245 >,
			< 1036800000  810000 267 >,
			< 1113600000  820000 289 >,
			< 1190400000  830000 313 >,
			< 1267200000  840000 336 >,
			< 1344000000  850000 360 >,
			< 1420800000  860000 383 >,
			< 1497600000  870000 409 >,
			< 1574400000  875000 435 >,
			< 1651200000  885000 461 >,
			< 1728000000  895000 488 >,
			< 1804800000  905000 516 >,
			< 1881600000  915000 543 >,
			< 1958400000  920000 573 >,
			< 2035200000  930000 604 >,
			< 2112000000  940000 636 >,
			< 2150400000  950000 656 >;

		qcom,speed1-pvs0-bin-v0 =
			<          0       0   0 >,
			<  300000000  775000  72 >,
			<  345600000  775000  83 >,
			<  422400000  775000 101 >,
			<  499200000  780000 120 >,
			<  576000000  790000 139 >,
			<  652800000  800000 159 >,
			<  729600000  810000 180 >,
			<  806400000  820000 200 >,
			<  883200000  830000 221 >,
			<  960000000  840000 242 >,
			< 1036800000  850000 264 >,
			< 1113600000  865000 287 >,
			< 1190400000  875000 308 >,
			< 1267200000  890000 333 >,
			< 1344000000  900000 356 >,
			< 1420800000  915000 380 >,
			< 1497600000  925000 404 >,
			< 1574400000  940000 430 >,
			< 1651200000  955000 456 >,
			< 1728000000  970000 482 >,
			< 1804800000  985000 510 >,
			< 1881600000 1000000 538 >,
			< 1958400000 1015000 565 >,
			< 2035200000 1030000 596 >,
			< 2112000000 1045000 627 >,
			< 2188800000 1060000 659 >,
			< 2265600000 1075000 691 >;

		qcom,speed1-pvs1-bin-v0 =
			<          0       0   0 >,
			<  300000000  775000  72 >,
			<  345600000  775000  83 >,
			<  422400000  775000 101 >,
			<  499200000  775000 120 >,
			<  576000000  775000 139 >,
			<  652800000  785000 159 >,
			<  729600000  795000 180 >,
			<  806400000  805000 200 >,
			<  883200000  815000 221 >,
			<  960000000  825000 242 >,
			< 1036800000  835000 264 >,
			< 1113600000  850000 287 >,
			< 1190400000  860000 308 >,
			< 1267200000  870000 333 >,
			< 1344000000  885000 356 >,
			< 1420800000  895000 380 >,
			< 1497600000  905000 404 >,
			< 1574400000  920000 430 >,
			< 1651200000  935000 456 >,
			< 1728000000  950000 482 >,
			< 1804800000  965000 510 >,
			< 1881600000  980000 538 >,
			< 1958400000  995000 565 >,
			< 2035200000 1005000 596 >,
			< 2112000000 1020000 627 >,
			< 2188800000 1035000 659 >,
			< 2265600000 1050000 691 >;

		qcom,speed1-pvs2-bin-v0 =
			<          0       0   0 >,
			<  300000000  750000  72 >,
			<  345600000  750000  83 >,
			<  422400000  750000 101 >,
			<  499200000  750000 120 >,
			<  576000000  760000 139 >,
			<  652800000  770000 159 >,
			<  729600000  780000 180 >,
			<  806400000  790000 200 >,
			<  883200000  800000 221 >,
			<  960000000  810000 242 >,
			< 1036800000  820000 264 >,
			< 1113600000  830000 287 >,
			< 1190400000  840000 308 >,
			< 1267200000  850000 333 >,
			< 1344000000  865000 356 >,
			< 1420800000  875000 380 >,
			< 1497600000  885000 404 >,
			< 1574400000  900000 430 >,
			< 1651200000  915000 456 >,
			< 1728000000  930000 482 >,
			< 1804800000  945000 510 >,
			< 1881600000  955000 538 >,
			< 1958400000  970000 565 >,
			< 2035200000  980000 596 >,
			< 2112000000  995000 627 >,
			< 2188800000 1010000 659 >,
			< 2265600000 1025000 691 >;

		qcom,speed1-pvs3-bin-v0 =
			<          0       0   0 >,
			<  300000000  750000  72 >,
			<  345600000  750000  83 >,
			<  422400000  750000 101 >,
			<  499200000  750000 120 >,
			<  576000000  750000 139 >,
			<  652800000  755000 159 >,
			<  729600000  765000 180 >,
			<  806400000  775000 200 >,
			<  883200000  785000 221 >,
			<  960000000  795000 242 >,
			< 1036800000  805000 264 >,
			< 1113600000  815000 287 >,
			< 1190400000  825000 308 >,
			< 1267200000  835000 333 >,
			< 1344000000  850000 356 >,
			< 1420800000  860000 380 >,
			< 1497600000  870000 404 >,
			< 1574400000  885000 430 >,
			< 1651200000  900000 456 >,
			< 1728000000  910000 482 >,
			< 1804800000  925000 510 >,
			< 1881600000  935000 538 >,
			< 1958400000  945000 565 >,
			< 2035200000  960000 596 >,
			< 2112000000  970000 627 >,
			< 2188800000  985000 659 >,
			< 2265600000 1000000 691 >;

		qcom,speed1-pvs4-bin-v0 =
			<          0       0   0 >,
			<  300000000  750000  72 >,
			<  345600000  750000  83 >,
			<  422400000  750000 101 >,
			<  499200000  750000 120 >,
			<  576000000  750000 139 >,
			<  652800000  750000 159 >,
			<  729600000  755000 180 >,
			<  806400000  765000 200 >,
			<  883200000  775000 221 >,
			<  960000000  785000 242 >,
			< 1036800000  795000 264 >,
			< 1113600000  805000 287 >,
			< 1190400000  815000 308 >,
			< 1267200000  825000 333 >,
			< 1344000000  835000 356 >,
			< 1420800000  845000 380 >,
			< 1497600000  855000 404 >,
			< 1574400000  870000 430 >,
			< 1651200000  885000 456 >,
			< 1728000000  895000 482 >,
			< 1804800000  905000 510 >,
			< 1881600000  915000 538 >,
			< 1958400000  925000 565 >,
			< 2035200000  935000 596 >,
			< 2112000000  950000 627 >,
			< 2188800000  960000 659 >,
			< 2265600000  975000 691 >;

		qcom,speed1-pvs5-bin-v0 =
			<          0       0   0 >,
			<  300000000  725000  72 >,
			<  345600000  725000  83 >,
			<  422400000  725000 101 >,
			<  499200000  725000 120 >,
			<  576000000  725000 139 >,
			<  652800000  735000 159 >,
			<  729600000  745000 180 >,
			<  806400000  755000 200 >,
			<  883200000  765000 221 >,
			<  960000000  775000 242 >,
			< 1036800000  785000 264 >,
			< 1113600000  795000 287 >,
			< 1190400000  805000 308 >,
			< 1267200000  815000 333 >,
			< 1344000000  825000 356 >,
			< 1420800000  835000 380 >,
			< 1497600000  845000 404 >,
			< 1574400000  855000 430 >,
			< 1651200000  865000 456 >,
			< 1728000000  875000 482 >,
			< 1804800000  885000 510 >,
			< 1881600000  895000 538 >,
			< 1958400000  905000 565 >,
			< 2035200000  915000 596 >,
			< 2112000000  930000 627 >,
			< 2188800000  940000 659 >,
			< 2265600000  950000 691 >;

		qcom,speed1-pvs6-bin-v0 =
			<          0       0   0 >,
			<  300000000  725000  72 >,
			<  345600000  725000  83 >,
			<  422400000  725000 101 >,
			<  499200000  725000 120 >,
			<  576000000  725000 139 >,
			<  652800000  725000 159 >,
			<  729600000  735000 180 >,
			<  806400000  745000 200 >,
			<  883200000  755000 221 >,
			<  960000000  765000 242 >,
			< 1036800000  775000 264 >,
			< 1113600000  785000 287 >,
			< 1190400000  795000 308 >,
			< 1267200000  805000 333 >,
			< 1344000000  815000 356 >,
			< 1420800000  825000 380 >,
			< 1497600000  835000 404 >,
			< 1574400000  845000 430 >,
			< 1651200000  850000 456 >,
			< 1728000000  860000 482 >,
			< 1804800000  870000 510 >,
			< 1881600000  880000 538 >,
			< 1958400000  890000 565 >,
			< 2035200000  895000 596 >,
			< 2112000000  905000 627 >,
			< 2188800000  915000 659 >,
			< 2265600000  925000 691 >;
	};

	qcom,cpubw {
		compatible = "qcom,cpubw";
		qcom,cpu-mem-ports = <1 512>, <2 512>;
		qcom,bw-tbl =
			<  572 /*  75 MHz */ >,
			< 1144 /* 150 MHz */ >,
			< 1525 /* 200 MHz */ >,
			< 2342 /* 307 MHz */ >,
			< 3509 /* 460 MHz */ >,
			< 4684 /* 614 MHz */ >,
			< 6103 /* 800 MHz */ >,
			< 7102 /* 931 MHz */ >;
	};

	qcom,msm-cpufreq@0 {
		reg = <0 4>;
		compatible = "qcom,msm-cpufreq";
		qcom,cpufreq-table =
			<  300000  300000  572 >,
			<  422400  422400 1144 >,
			<  652800  499200 1525 >,
			<  729600  576000 2342 >,
			<  883200  576000 2342 >,
			<  960000  960000 3509 >,
			< 1036800 1036800 3509 >,
			< 1190400 1036800 3509 >,
			< 1267200 1267200 4684 >,
			< 1497600 1497600 4684 >,
			< 1574400 1574400 6103 >,
			< 1728000 1651200 6103 >,
			< 1958400 1728000 7102 >,
			< 2265600 1728000 7102 >,
			< 2457600 1728000 7102 >;
	};

	usb3: qcom,ssusb@f9200000 {
		compatible = "qcom,dwc-usb3-msm";
		reg = <0xf9200000 0xfc000>;
		interrupts = <0 131 0 0 179 0>;
		interrupt-names = "irq", "otg_irq";
		SSUSB_VDDCX-supply = <&pm8841_s2>;
		SSUSB_1p8-supply = <&pm8941_l6>;
		HSUSB_VDDCX-supply = <&pm8841_s2>;
		HSUSB_1p8-supply = <&pm8941_l6>;
		HSUSB_3p3-supply = <&pm8941_l24>;
		qcom,dwc-usb3-msm-dbm-eps = <4>;

		qcom,msm-bus,name = "usb3";
		qcom,msm-bus,num-cases = <2>;
		qcom,msm-bus,active-only = <0>;
		qcom,msm-bus,num-paths = <1>;
		qcom,msm-bus,vectors-KBps =
				<61 512 0 0>,
				<61 512 240000 960000>;
	};

	gdsc_oxili_gx: qcom,gdsc@fd8c4024 {
		parent-supply = <&pm8841_s4>;
	};

	qcom,lpass@fe200000 {
		compatible = "qcom,pil-q6v5-lpass";
		reg = <0xfe200000 0x00100>,
		      <0xfd485100 0x00010>;

		qcom,firmware-name = "adsp";
	};

	qcom,msm-pcm {
		compatible = "qcom,msm-pcm-dsp";
	};

	qcom,msm-pcm-routing {
		compatible = "qcom,msm-pcm-routing";
	};

	qcom,msm-pcm-lpa {
		compatible = "qcom,msm-pcm-lpa";
	};

	qcom,msm-compr-dsp {
		compatible = "qcom,msm-compr-dsp";
	};

	qcom,msm-voip-dsp {
		compatible = "qcom,msm-voip-dsp";
	};

	qcom,msm-stub-codec {
		compatible = "qcom,msm-stub-codec";
	};

	qcom,msm-dai-fe {
		compatible = "qcom,msm-dai-fe";
	};

	qcom,msm-dai-q6 {
		compatible = "qcom,msm-dai-q6";
		qcom,msm-dai-q6-sb-0-rx {
			compatible = "qcom,msm-dai-q6-dev";
			qcom,msm-dai-q6-dev-id = <16384>;
		};

		qcom,msm-dai-q6-sb-0-tx {
			compatible = "qcom,msm-dai-q6-dev";
			qcom,msm-dai-q6-dev-id = <16385>;
		};
	};

	qcom,msm-auxpcm {
		compatible = "qcom,msm-auxpcm-resource";
		qcom,msm-cpudai-auxpcm-clk = "pcm_clk";
		qcom,msm-cpudai-auxpcm-mode = <0>;
		qcom,msm-cpudai-auxpcm-sync = <1>;
		qcom,msm-cpudai-auxpcm-frame = <5>;
		qcom,msm-cpudai-auxpcm-quant = <2>;
		qcom,msm-cpudai-auxpcm-slot = <1>;
		qcom,msm-cpudai-auxpcm-data = <0>;
		qcom,msm-cpudai-auxpcm-pcm-clk-rate = <2048000>;

		qcom,msm-auxpcm-rx {
			qcom,msm-auxpcm-dev-id = <4106>;
			compatible = "qcom,msm-auxpcm-dev";
		};

		qcom,msm-auxpcm-tx {
			qcom,msm-auxpcm-dev-id = <4107>;
			compatible = "qcom,msm-auxpcm-dev";
		};
	};

	qcom,msm-pcm-hostless {
		compatible = "qcom,msm-pcm-hostless";
	};

	qcom,msm-ocmem-audio {
		compatible = "qcom,msm-ocmem-audio";
		qcom,msm-bus,name = "audio-ocmem";
		qcom,msm-bus,num-cases = <2>;
		qcom,msm-bus,active-only = <0>;
		qcom,msm-bus,num-paths = <1>;
		qcom,msm-bus,vectors-KBps =
			<11 604 0 0>,
			<11 604 32506 32506>;
	};

	qcom,mss@fc880000 {
		compatible = "qcom,pil-q6v5-mss";
		reg = <0xfc880000 0x100>,
		      <0xfd485000 0x400>,
		      <0xfc820000 0x020>,
		      <0xfc401680 0x004>,
		      <0xfc980008 0x004>;
		vdd_mss-supply = <&pm8841_s3>;

		qcom,firmware-name = "mba";
		qcom,pil-self-auth = <1>;
	};

	qcom,mba@fc820000 {
		compatible = "qcom,pil-mba";
		reg = <0xfc820000 0x0020>,
		      <0x0d1fc000 0x4000>;

		qcom,firmware-name = "modem";
		qcom,depends-on    = "mba";
	};

	qcom,pronto@fb21b000 {
		compatible = "qcom,pil-pronto";
		reg = <0xfb21b000 0x3000>,
		      <0xfc401700 0x4>,
		      <0xfd485300 0xc>;
		vdd_pronto_pll-supply = <&pm8941_l12>;

		qcom,firmware-name = "wcnss";
	};

	qcom,ocmem@fdd00000 {
		compatible = "qcom,msm-ocmem";
		reg = <0xfdd00000 0x2000>,
		      <0xfdd02000 0x2000>,
		      <0xfe039000 0x400>,
		      <0xfec00000 0x180000>;
		reg-names = "ocmem_ctrl_physical", "dm_ctrl_physical", "br_ctrl_physical", "ocmem_physical";
		interrupts = <0 76 0 0 77 0>;
		interrupt-names = "ocmem_irq", "dm_irq";
		qcom,ocmem-num-regions = <0x3>;
		qcom,resource-type = <0x706d636f>;
		#address-cells = <1>;
		#size-cells = <1>;
		ranges = <0x0 0xfec00000 0x180000>;

		partition@0 {
			reg = <0x0 0x100000>;
			qcom,ocmem-part-name = "graphics";
			qcom,ocmem-part-min = <0x80000>;
		};

		partition@80000 {
			reg = <0x80000 0xA0000>;
			qcom,ocmem-part-name = "lp_audio";
			qcom,ocmem-part-min = <0xA0000>;
		};

		partition@E0000 {
			reg = <0x120000 0x20000>;
			qcom,ocmem-part-name = "other_os";
			qcom,ocmem-part-min = <0x20000>;
		};

		partition@100000 {
			reg = <0x100000 0x80000>;
			qcom,ocmem-part-name = "video";
			qcom,ocmem-part-min = <0x55000>;
		};

		partition@140000 {
			reg = <0x140000 0x40000>;
			qcom,ocmem-part-name = "sensors";
			qcom,ocmem-part-min = <0x40000>;
		};
	};

	rpm_bus: qcom,rpm-smd {
		compatible = "qcom,rpm-smd";
		rpm-channel-name = "rpm_requests";
		rpm-channel-type = <15>; /* SMD_APPS_RPM */
	};

        qcom,msm-rng@f9bff000 {
               compatible = "qcom,msm-rng";
               reg = <0xf9bff000 0x200>;
        };

	qcom,qseecom@fe806000 {
		compatible = "qcom,qseecom";
		qcom,msm-bus,name = "qseecom-noc";
		qcom,msm-bus,num-cases = <4>;
		qcom,msm-bus,active-only = <0>;
		qcom,msm-bus,num-paths = <1>;
		qcom,msm-bus,vectors-KBps =
				<55 512 0 0>,
				<55 512 3936000 393600>,
				<55 512 3936000 393600>,
				<55 512 3936000 393600>;
	};

	qcom,wdt@f9017000 {
		compatible = "qcom,msm-watchdog";
		reg = <0xf9017000 0x1000>;
		interrupts = <0 3 0 0 4 0>;
		qcom,bark-time = <11000>;
		qcom,pet-time = <10000>;
		qcom,ipi-ping = <1>;
	};

	qcom,tz-log@fe805720 {
		compatible = "qcom,tz-log";
		reg = <0xfe805720 0x1000>;
	};

	qcom,venus@fdce0000 {
		compatible = "qcom,pil-venus";
		reg = <0xfdce0000 0x4000>,
		      <0xfdc80208 0x8>;
		vdd-supply = <&gdsc_venus>;

		qcom,firmware-name = "venus";
		qcom,firmware-min-paddr = <0xF500000>;
		qcom,firmware-max-paddr = <0xFA00000>;
	};

	qcom,cache_erp {
		compatible = "qcom,cache_erp";
		interrupts = <1 9 0>, <0 2 0>;
		interrupt-names = "l1_irq", "l2_irq";
	};

	tsens@fc4a8000 {
		compatible = "qcom,msm-tsens";
		reg = <0xfc4a8000 0x2000>,
		      <0xfc4b80d0 0x5>;
		reg-names = "tsens_physical", "tsens_eeprom_physical";
		interrupts = <0 184 0>;
		qcom,sensors = <11>;
		qcom,slope = <3200 3200 3200 3200 3200 3200 3200 3200 3200
				3200 3200>;
	};

	qcom,msm-rtb {
		compatible = "qcom,msm-rtb";
		qcom,memory-reservation-type = "EBI1";
		qcom,memory-reservation-size = <0x100000>; /* 1M EBI1 buffer */
	};

        qcom,qcedev@fd440000 {
		compatible = "qcom,qcedev";
		reg = <0xfd440000 0x20000>,
		      <0xfd444000 0x8000>;
		reg-names = "crypto-base","crypto-bam-base";
		interrupts = <0 235 0>;
		qcom,bam-pipe-pair = <0>;
	};

        qcom,qcrypto@fd444000 {
		compatible = "qcom,qcrypto";
		reg = <0xfd440000 0x20000>,
		      <0xfd444000 0x8000>;
		reg-names = "crypto-base","crypto-bam-base";
		interrupts = <0 235 0>;
		qcom,bam-pipe-pair = <1>;
	};

	qcom,usbbam@f9304000 {
		compatible = "qcom,usb-bam-msm";
		reg = <0xf9304000 0x9000>;
		interrupts = <0 132 0>;
		qcom,usb-active-bam = <0>;
		qcom,usb-total-bam-num = <1>;
		qcom,usb-bam-num-pipes = <16>;
		qcom,usb-base-address = <0xf9200000>;

		qcom,pipe1 {
			label = "usb-to-peri-qdss-dwc3";
			qcom,usb-bam-type = <0>;
			qcom,src-bam-physical-address = <0>;
			qcom,src-bam-pipe-index = <0>;
			qcom,dst-bam-physical-address = <0>;
			qcom,dst-bam-pipe-index = <0>;
			qcom,data-fifo-offset = <0>;
			qcom,data-fifo-size = <0>;
			qcom,descriptor-fifo-offset = <0>;
			qcom,descriptor-fifo-size = <0>;
		};

		qcom,pipe2 {
			label = "peri-to-usb-qdss-dwc3";
			qcom,usb-bam-type = <0>;
			qcom,src-bam-physical-address = <0xfc37C000>;
			qcom,src-bam-pipe-index = <0>;
			qcom,dst-bam-physical-address = <0xf9304000>;
			qcom,dst-bam-pipe-index = <2>;
			qcom,data-fifo-offset = <0xf0000>;
			qcom,data-fifo-size = <0x4000>;
			qcom,descriptor-fifo-offset = <0xf4000>;
			qcom,descriptor-fifo-size = <0x1400>;
		};
	};

	qcom,msm-thermal {
		compatible = "qcom,msm-thermal";
		qcom,sensor-id = <0>;
		qcom,poll-ms = <250>;
		qcom,limit-temp = <60>;
		qcom,temp-hysteresis = <10>;
		qcom,freq-step = <2>;
	};

	gpio_keys {
		compatible = "gpio-keys";

		camera_snapshot {
			label = "camera_snapshot";
			gpios = <&pm8941_gpios 3 0x1>;
			linux,input-type = <1>;
			linux,code = <0x2fe>;
			gpio-key,wakeup;
			debounce-interval = <15>;
		};

		camera_focus {
			label = "camera_focus";
			gpios = <&pm8941_gpios 4 0x1>;
			linux,input-type = <1>;
			linux,code = <0x210>;
			gpio-key,wakeup;
			debounce-interval = <15>;
		};

		vol_up {
			label = "volume_up";
			gpios = <&pm8941_gpios 5 0x1>;
			linux,input-type = <1>;
			linux,code = <115>;
			gpio-key,wakeup;
			debounce-interval = <15>;
		};
	};
};

/include/ "msm-pm8x41-rpm-regulator.dtsi"
/include/ "msm-pm8841.dtsi"
/include/ "msm-pm8941.dtsi"
/include/ "msm8974-regulator.dtsi"
/include/ "msm8974-gpio.dtsi"
